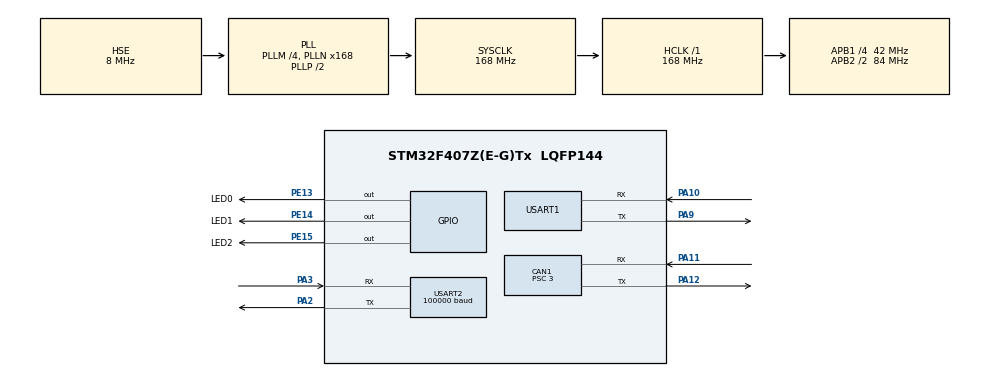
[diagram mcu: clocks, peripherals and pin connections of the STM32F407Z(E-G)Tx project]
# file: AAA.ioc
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CAN1.ABOM=ENABLE
CAN1.BS1=CAN_BS1_9TQ
CAN1.BS2=CAN_BS2_4TQ
CAN1.CalculateTimeQuantum=71.42857142857143
CAN1.Prescaler=3
Dma.Request0=USART2_RX
Dma.USART2_RX.0.Direction=DMA_PERIPH_TO_MEMORY
Dma.USART2_RX.0.FIFOMode=DMA_FIFOMODE_DISABLE
Dma.USART2_RX.0.Instance=DMA1_Stream5
Dma.USART2_RX.0.MemDataAlignment=DMA_MDATAALIGN_BYTE
Dma.USART2_RX.0.MemInc=DMA_MINC_ENABLE
Dma.USART2_RX.0.Mode=DMA_NORMAL
Dma.USART2_RX.0.PeriphDataAlignment=DMA_PDATAALIGN_BYTE
Dma.USART2_RX.0.PeriphInc=DMA_PINC_DISABLE
Dma.USART2_RX.0.Priority=DMA_PRIORITY_LOW
Mcu.Family=STM32F4
Mcu.Name=STM32F407Z(E-G)Tx
Mcu.Package=LQFP144
NVIC.CAN1_RX0_IRQn=true\:0\:0\:false\:false\:true\:true\:true
NVIC.CAN1_TX_IRQn=true\:0\:0\:false\:false\:true\:true\:true
NVIC.DMA1_Stream5_IRQn=true\:0\:0\:false\:false\:true\:false\:true
NVIC.PriorityGroup=NVIC_PRIORITYGROUP_4
NVIC.TIM3_IRQn=true\:0\:0\:false\:false\:true\:true\:true
NVIC.TIM4_IRQn=true\:0\:0\:false\:false\:true\:true\:true
NVIC.TIM7_IRQn=true\:0\:0\:false\:false\:true\:true\:true
NVIC.USART1_IRQn=true\:0\:0\:false\:false\:true\:true\:true
NVIC.USART2_IRQn=true\:0\:0\:false\:false\:true\:true\:true
PA10.Mode=Asynchronous
PA10.Signal=USART1_RX
PA11.Mode=Master
PA11.Signal=CAN1_RX
PA12.Mode=Master
PA12.Signal=CAN1_TX
PA13.Mode=Serial_Wire
PA13.Signal=SYS_JTMS-SWDIO
PA14.Mode=Serial_Wire
PA14.Signal=SYS_JTCK-SWCLK
PA2.Mode=Asynchronous
PA2.Signal=USART2_TX
PA3.Mode=Asynchronous
PA3.Signal=USART2_RX
PA9.Mode=Asynchronous
PA9.Signal=USART1_TX
PE13.GPIO_Label=LED0
PE13.GPIO_PuPd=GPIO_PULLUP
PE13.PinState=GPIO_PIN_SET
PE13.Signal=GPIO_Output
PE14.GPIO_Label=LED1
PE14.GPIO_PuPd=GPIO_PULLUP
PE14.PinState=GPIO_PIN_SET
PE14.Signal=GPIO_Output
PE15.GPIO_Label=LED2
PE15.GPIO_PuPd=GPIO_PULLUP
PE15.PinState=GPIO_PIN_SET
PE15.Signal=GPIO_Output
PH0-OSC_IN.Mode=HSE-External-Oscillator
PH0-OSC_IN.Signal=RCC_OSC_IN
PH1-OSC_OUT.Mode=HSE-External-Oscillator
PH1-OSC_OUT.Signal=RCC_OSC_OUT
ProjectManager.HeapSize=0x200
ProjectManager.StackSize=0x400
ProjectManager.TargetToolchain=MDK-ARM V5
RCC.48MHZClocksFreq_Value=84000000
RCC.AHBFreq_Value=168000000
RCC.APB1CLKDivider=RCC_HCLK_DIV4
RCC.APB1Freq_Value=42000000
RCC.APB1TimFreq_Value=84000000
RCC.APB2CLKDivider=RCC_HCLK_DIV2
RCC.APB2Freq_Value=84000000
RCC.APB2TimFreq_Value=168000000
RCC.CortexFreq_Value=168000000
RCC.HCLKFreq_Value=168000000
RCC.HSE_VALUE=8000000
RCC.HSI_VALUE=16000000
RCC.LSE_VALUE=32768
RCC.PLLM=4
RCC.PLLN=168
RCC.PLLSourceVirtual=RCC_PLLSOURCE_HSE
RCC.SYSCLKFreq_VALUE=168000000
RCC.SYSCLKSource=RCC_SYSCLKSOURCE_PLLCLK
RCC.VCOOutputFreq_Value=336000000
TIM3.Period=1000-1
TIM3.Prescaler=84-1
TIM4.ClockDivision=TIM_CLOCKDIVISION_DIV2
TIM4.Period=5
TIM4.Prescaler=8400
TIM7.Period=1000
TIM7.Prescaler=8400
USART1.VirtualMode=VM_ASYNC
USART2.BaudRate=100000
USART2.Parity=PARITY_EVEN
USART2.VirtualMode=VM_ASYNC
VP_TIM3_VS_ClockSourceINT.Mode=Internal
VP_TIM4_VS_ClockSourceINT.Mode=Internal
VP_TIM7_VS_ClockSourceINT.Mode=Enable_Timer
board=custom

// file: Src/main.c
/* USER CODE BEGIN Header */
/**
  ******************************************************************************
  * @file           : main.c
  * @brief          : Main program body
  ******************************************************************************
  * @attention
  *
  * <h2><center>&copy; Copyright (c) 2019 STMicroelectronics.
  * All rights reserved.</center></h2>
  *
  * This software component is licensed by ST under BSD 3-Clause license,
  * the "License"; You may not use this file except in compliance with the
  * License. You may obtain a copy of the License at:
  *                        opensource.org/licenses/BSD-3-Clause
  *
  ******************************************************************************
  */
/* USER CODE END Header */

#include "main.h"
#include "can.h"
#include "dma.h"
#include "tim.h"
#include "usart.h"
#include "gpio.h"
#include "aaa.h"
#include "led.h"

void SystemClock_Config(void);

int main(void)
{

  /* MCU Configuration--------------------------------------------------------*/

  /* Reset of all peripherals, Initializes the Flash interface and the Systick. */
  HAL_Init();

  /* USER CODE BEGIN Init */
LED_Init();
  /* USER CODE END Init */

  /* Configure the system clock */
  SystemClock_Config();

  /* Initialize all configured peripherals */
  MX_GPIO_Init();
  MX_DMA_Init();
  MX_CAN1_Init();
  MX_TIM3_Init();
  MX_USART1_UART_Init();
  MX_USART2_UART_Init();
  MX_TIM4_Init();
  MX_TIM7_Init();
	can_user_init(&hcan1);

  /* Infinite loop */
  while (1)
  {

  }
}

void SystemClock_Config(void)
{
  RCC_OscInitTypeDef RCC_OscInitStruct = {0};
  RCC_ClkInitTypeDef RCC_ClkInitStruct = {0};

  /** Configure the main internal regulator output voltage
  */
  __HAL_RCC_PWR_CLK_ENABLE();
  __HAL_PWR_VOLTAGESCALING_CONFIG(PWR_REGULATOR_VOLTAGE_SCALE1);
  /** Initializes the CPU, AHB and APB busses clocks
  */
  RCC_OscInitStruct.OscillatorType = RCC_OSCILLATORTYPE_HSE;
  RCC_OscInitStruct.HSEState = RCC_HSE_ON;
  RCC_OscInitStruct.PLL.PLLState = RCC_PLL_ON;
  RCC_OscInitStruct.PLL.PLLSource = RCC_PLLSOURCE_HSE;
  RCC_OscInitStruct.PLL.PLLM = 4;
  RCC_OscInitStruct.PLL.PLLN = 168;
  RCC_OscInitStruct.PLL.PLLP = RCC_PLLP_DIV2;
  RCC_OscInitStruct.PLL.PLLQ = 4;
  if (HAL_RCC_OscConfig(&RCC_OscInitStruct) != HAL_OK)
  {
    Error_Handler();
  }
  /** Initializes the CPU, AHB and APB busses clocks
  */
  RCC_ClkInitStruct.ClockType = RCC_CLOCKTYPE_HCLK|RCC_CLOCKTYPE_SYSCLK
                              |RCC_CLOCKTYPE_PCLK1|RCC_CLOCKTYPE_PCLK2;
  RCC_ClkInitStruct.SYSCLKSource = RCC_SYSCLKSOURCE_PLLCLK;
  RCC_ClkInitStruct.AHBCLKDivider = RCC_SYSCLK_DIV1;
  RCC_ClkInitStruct.APB1CLKDivider = RCC_HCLK_DIV4;
  RCC_ClkInitStruct.APB2CLKDivider = RCC_HCLK_DIV2;

  if (HAL_RCC_ClockConfig(&RCC_ClkInitStruct, FLASH_LATENCY_5) != HAL_OK)
  {
    Error_Handler();
  }
}

void Error_Handler(void)
{
  /* USER CODE BEGIN Error_Handler_Debug */
  /* User can add his own implementation to report the HAL error return state */
LED2_On();
  /* USER CODE END Error_Handler_Debug */
}

/************************ (C) COPYRIGHT STMicroelectronics *****END OF FILE****/
